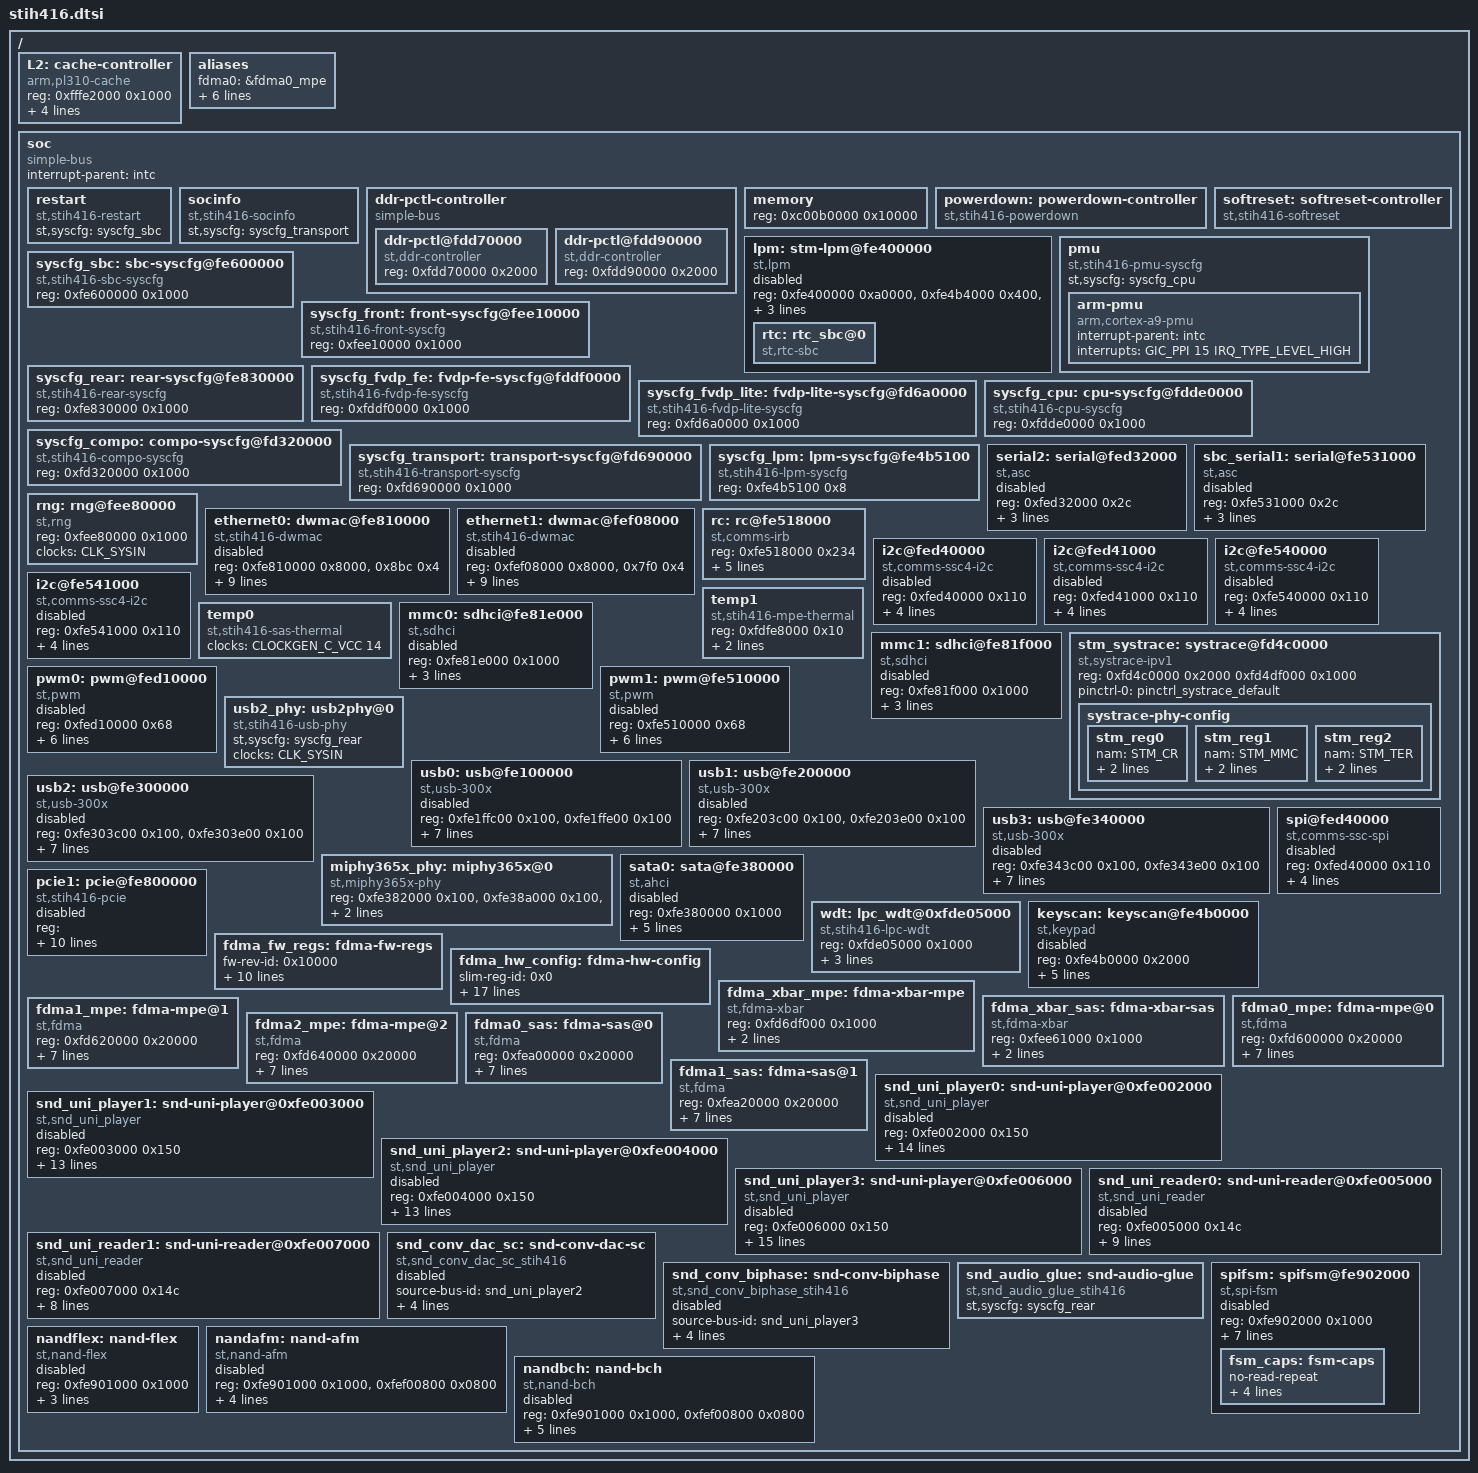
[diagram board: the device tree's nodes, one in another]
/*
 * Copyright (C) 2012 STMicroelectronics Limited.
 * Author: Srinivas Kandagatla <srinivas.kandagatla@st.com>
 *
 * This program is free software; you can redistribute it and/or modify
 * it under the terms of the GNU General Public License version 2 as
 * publishhed by the Free Software Foundation.
 */
#include <dt-bindings/interrupt-controller/arm-gic.h>
#include <dt-bindings/reset-controller/stih416-resets.h>
#include <dt-bindings/phy/phy-miphy365x.h>
#include "stih41x.dtsi"
#include "stih416-clock.dtsi"
#include "stih416-pinctrl.dtsi"
/ {
	L2: cache-controller {
		compatible = "arm,pl310-cache";
		reg = <0xfffe2000 0x1000>;
		arm,data-latency = <3 3 3>;
		arm,tag-latency = <2 2 2>;
		cache-unified;
		cache-level = <2>;
	};

	aliases {
		fdma0 = &fdma0_mpe;
		fdma1 = &fdma1_mpe;
		fdma2 = &fdma2_mpe;
		fdma3 = &fdma0_sas;
		fdma4 = &fdma1_sas;
		fdmaxbar0 = &fdma_xbar_mpe;
		fdmaxbar1 = &fdma_xbar_sas;
	};

	soc {
		#address-cells = <1>;
		#size-cells = <1>;
		interrupt-parent = <&intc>;
		ranges;
		compatible = "simple-bus";

		restart {
			compatible = "st,stih416-restart";
			st,syscfg = <&syscfg_sbc>;
		};

		socinfo {
			compatible = "st,stih416-socinfo";
			st,syscfg = <&syscfg_transport>;
		};

		ddr-pctl-controller {
			#address-cells = <1>;
			#size-cells = <1>;
			ranges;
			compatible = "simple-bus";
			ddr-pctl@fdd70000 {
				compatible = "st,ddr-controller";
				reg = <0xfdd70000 0x2000>;
			};
			ddr-pctl@fdd90000 {
				compatible = "st,ddr-controller";
				reg = <0xfdd90000 0x2000>;
			};
		};

		memory {
			device_type = "eram";
			reg = <0xc00b0000 0x10000>;
			reg-names = "eram_1";
		};

		powerdown: powerdown-controller {
			#reset-cells = <1>;
			compatible = "st,stih416-powerdown";
		};

		lpm:stm-lpm@fe400000 {
			compatible = "st,lpm";
			reg = <0xfe400000 0xa0000>,
			      <0xfe4b4000 0x400>,
			      <0xfe4b5100 0x100>,
			      <0x020000 0x0>;
			reg-names = "base", "mailbox", "confreg", "pmem";
			interrupts = <GIC_SPI 215 IRQ_TYPE_NONE>;
			st,fw_name = "lpm-fw-STiH416.elf";
			status = "disabled";

			rtc: rtc_sbc@0 {
				compatible = "st,rtc-sbc";
			};
		};

		softreset: softreset-controller {
			#reset-cells = <1>;
			compatible = "st,stih416-softreset";
		};

		pmu {
			compatible = "st,stih416-pmu-syscfg";
			st,syscfg = <&syscfg_cpu>;

			arm-pmu {
				interrupt-parent = <&intc>;
				compatible = "arm,cortex-a9-pmu";
				interrupts = <GIC_PPI 15 IRQ_TYPE_LEVEL_HIGH>;
			};
		};

		syscfg_sbc:sbc-syscfg@fe600000{
			compatible = "st,stih416-sbc-syscfg", "syscon";
			reg = <0xfe600000 0x1000>;
		};

		syscfg_front:front-syscfg@fee10000{
			compatible = "st,stih416-front-syscfg", "syscon";
			reg = <0xfee10000 0x1000>;
		};

		syscfg_rear:rear-syscfg@fe830000{
			compatible = "st,stih416-rear-syscfg", "syscon";
			reg = <0xfe830000 0x1000>;
		};

		/* MPE */
		syscfg_fvdp_fe:fvdp-fe-syscfg@fddf0000{
			compatible = "st,stih416-fvdp-fe-syscfg", "syscon";
			reg = <0xfddf0000 0x1000>;
		};

		syscfg_fvdp_lite:fvdp-lite-syscfg@fd6a0000{
			compatible = "st,stih416-fvdp-lite-syscfg", "syscon";
			reg = <0xfd6a0000 0x1000>;
		};

		syscfg_cpu:cpu-syscfg@fdde0000{
			compatible = "st,stih416-cpu-syscfg", "syscon";
			reg = <0xfdde0000 0x1000>;
		};

		syscfg_compo:compo-syscfg@fd320000{
			compatible = "st,stih416-compo-syscfg", "syscon";
			reg = <0xfd320000 0x1000>;
		};

		syscfg_transport:transport-syscfg@fd690000{
			compatible = "st,stih416-transport-syscfg", "syscon";
			reg = <0xfd690000 0x1000>;
		};

		syscfg_lpm:lpm-syscfg@fe4b5100{
			compatible = "st,stih416-lpm-syscfg", "syscon";
			reg = <0xfe4b5100 0x8>;
		};

		serial2: serial@fed32000{
			compatible = "st,asc";
			status = "disabled";
			reg = <0xfed32000 0x2c>;
			interrupts = <GIC_SPI 197 IRQ_TYPE_NONE>;
			clocks = <&CLK_S_A0_LS 0>;
			pinctrl-names = "default";
			pinctrl-0 = <&pinctrl_serial2 &pinctrl_serial2_oe>;
		};

		/* SBC_UART1 */
		sbc_serial1: serial@fe531000 {
			compatible = "st,asc";
			status = "disabled";
			reg = <0xfe531000 0x2c>;
			interrupts = <GIC_SPI 210 IRQ_TYPE_NONE>;
			pinctrl-names = "default";
			pinctrl-0 = <&pinctrl_sbc_serial1>;
			clocks = <&CLK_SYSIN>;
		};

		/* RNG */
		rng: rng@fee80000 {
			compatible = "st,rng";
			reg = <0xfee80000 0x1000>;
			clocks = <&CLK_SYSIN>;
		};

		ethernet0: dwmac@fe810000 {
			device_type = "network";
			status = "disabled";
			compatible = "st,stih416-dwmac", "snps,dwmac", "snps,dwmac-3.710";
			reg = <0xfe810000 0x8000>, <0x8bc 0x4>;
			reg-names = "stmmaceth", "sti-ethconf";
			st,syscon = <&syscfg_rear>;
			resets = <&softreset STIH416_ETH0_SOFTRESET>;
			reset-names = "stmmaceth";
			interrupts = <GIC_SPI 133 IRQ_TYPE_NONE>,
				     <GIC_SPI 134 IRQ_TYPE_NONE>,
				     <GIC_SPI 135 IRQ_TYPE_NONE>;

			interrupt-names = "macirq", "eth_wake_irq", "eth_lpi";

			snps,pbl = <32>;
			snps,mixed-burst;

			pinctrl-names = "default";
			pinctrl-0 = <&pinctrl_mii0>;
			clock-names = "stmmaceth",
				      "sti-ethclk";
			clocks = <&CLK_S_A1_LS 0>,
				 <&CLK_S_A1_LS 3>;
		};

		ethernet1: dwmac@fef08000 {
			device_type = "network";
			status = "disabled";
			compatible = "st,stih416-dwmac", "snps,dwmac", "snps,dwmac-3.710";
			reg = <0xfef08000 0x8000>, <0x7f0 0x4>;
			reg-names = "stmmaceth", "sti-ethconf";
			st,syscon = <&syscfg_sbc>;
			resets = <&softreset STIH416_ETH1_SOFTRESET>;
			reset-names = "stmmaceth";

			interrupts = <GIC_SPI 136 IRQ_TYPE_NONE>,
				     <GIC_SPI 137 IRQ_TYPE_NONE>,
				     <GIC_SPI 138 IRQ_TYPE_NONE>;

			interrupt-names = "macirq",
					  "eth_wake_irq",
					  "eth_lpi";

			snps,pbl = <32>;
			snps,mixed-burst;

			pinctrl-names = "default";
			pinctrl-0 = <&pinctrl_mii1>;
			clock-names = "stmmaceth", "sti-ethclk";
			clocks = <&CLK_S_A0_LS 0>,
				 <&CLK_S_A0_LS 4>;
		};

		rc: rc@fe518000 {
			compatible = "st,comms-irb";
			reg = <0xfe518000 0x234>;
			interrupts = <GIC_SPI 203 IRQ_TYPE_NONE>;
			rx-mode = "infrared";
			clocks = <&CLK_SYSIN>;
			pinctrl-names = "default";
			pinctrl-0 = <&pinctrl_ir>;
			resets = <&softreset STIH416_IRB_SOFTRESET>;
		};

		i2c@fed40000 {
			compatible = "st,comms-ssc4-i2c";
			reg = <0xfed40000 0x110>;
			interrupts = <GIC_SPI 187 IRQ_TYPE_LEVEL_HIGH>;
			#address-cells = <1>;
			#size-cells = <0>;
			clocks = <&CLK_S_A0_LS 0>;
			clock-names = "ssc";
			clock-frequency = <400000>;
			pinctrl-names = "default";
			pinctrl-0 = <&pinctrl_i2c0_default>;

			status = "disabled";
		};

		i2c@fed41000 {
			compatible = "st,comms-ssc4-i2c";
			reg = <0xfed41000 0x110>;
			interrupts = <GIC_SPI 188 IRQ_TYPE_LEVEL_HIGH>;
			#address-cells = <1>;
			#size-cells = <0>;
			clocks = <&CLK_S_A0_LS 0>;
			clock-names = "ssc";
			clock-frequency = <400000>;
			pinctrl-names = "default";
			pinctrl-0 = <&pinctrl_i2c1_default>;

			status = "disabled";
		};

		i2c@fe540000 {
			compatible = "st,comms-ssc4-i2c";
			reg = <0xfe540000 0x110>;
			interrupts = <GIC_SPI 206 IRQ_TYPE_LEVEL_HIGH>;
			#address-cells = <1>;
			#size-cells = <0>;
			clocks = <&CLK_SYSIN>;
			clock-names = "ssc";
			clock-frequency = <400000>;
			pinctrl-names = "default";
			pinctrl-0 = <&pinctrl_sbc_i2c0_default>;

			status = "disabled";
		};

		i2c@fe541000 {
			compatible = "st,comms-ssc4-i2c";
			reg = <0xfe541000 0x110>;
			interrupts = <GIC_SPI 207 IRQ_TYPE_LEVEL_HIGH>;
			#address-cells = <1>;
			#size-cells = <0>;
			clocks = <&CLK_SYSIN>;
			clock-names = "ssc";
			clock-frequency = <400000>;
			pinctrl-names = "default";
			pinctrl-0 = <&pinctrl_sbc_i2c1_default>;

			status = "disabled";
		};

		temp0{
			compatible = "st,stih416-sas-thermal";
			clock-names = "thermal";
			clocks = <&CLOCKGEN_C_VCC 14>;
		};

		temp1{
			compatible = "st,stih416-mpe-thermal";
			reg = <0xfdfe8000 0x10>;
			clock-names = "thermal";
			clocks = <&CLOCKGEN_E 3>;
			interrupts = <GIC_SPI 23 IRQ_TYPE_EDGE_RISING>;
		};

		mmc0: sdhci@fe81e000 {
			compatible = "st,sdhci";
			status = "disabled";
			reg = <0xfe81e000 0x1000>;
			interrupts = <GIC_SPI 127 IRQ_TYPE_NONE>;
			interrupt-names = "mmcirq";
			pinctrl-names = "default";
			pinctrl-0 = <&pinctrl_mmc0>;
			clock-names = "mmc";
			clocks = <&CLK_S_A1_LS 1>;
		};

		mmc1: sdhci@fe81f000 {
			compatible = "st,sdhci";
			status = "disabled";
			reg = <0xfe81f000 0x1000>;
			interrupts = <GIC_SPI 128 IRQ_TYPE_NONE>;
			interrupt-names = "mmcirq";
			pinctrl-names = "default";
			pinctrl-0 = <&pinctrl_mmc1>;
			clock-names = "mmc";
			clocks = <&CLK_S_A1_LS 8>;
		};

		stm_systrace: systrace@fd4c0000 {
			compatible = "st,systrace-ipv1";
			reg = <0xfd4c0000 0x2000
			       0xfd4df000 0x1000>;
			pinctrl-names = "default";
			pinctrl-0 = <&pinctrl_systrace_default>;

			/* STM IP v1 configuration */
			systrace-phy-config {
			    stm_reg0 { /* fck = 12.5Mhz */
				nam = "STM_CR";  ofs = <0x0000>; val = <0x00C0>;
			    };
			    stm_reg1 {
				nam = "STM_MMC"; ofs = <0x0008>; val = <0x0000>;
			    };
			    stm_reg2 { /* Enable all initiators */
				nam = "STM_TER"; ofs = <0x0010>; val = <0x023d>;
			    };
			};
		};

		/* SAS PWM MODULE */
		pwm0: pwm@fed10000 {
			compatible = "st,pwm";
			status = "disabled";
			#pwm-cells = <2>;
			reg = <0xfed10000 0x68>;
			pinctrl-names = "default";
			pinctrl-0 = <&pinctrl_pwm0_chan0_default
				     &pinctrl_pwm0_chan1_default
				     &pinctrl_pwm0_chan2_default
				     &pinctrl_pwm0_chan3_default>;
			clock-names = "pwm";
			clocks = <&CLK_SYSIN>;
			st,pwm-num-chan = <4>;
		};

		/* SBC PWM MODULE */
		pwm1: pwm@fe510000 {
			compatible = "st,pwm";
			status = "disabled";
			#pwm-cells = <2>;
			reg = <0xfe510000 0x68>;
			pinctrl-names = "default";
			pinctrl-0 = <&pinctrl_pwm1_chan0_default
				     &pinctrl_pwm1_chan1_default
				     &pinctrl_pwm1_chan2_default
				     &pinctrl_pwm1_chan3_default>;
			clock-names = "pwm";
			clocks = <&CLK_SYSIN>;
			st,pwm-num-chan = <4>;
		};

		usb2_phy: usb2phy@0 {
			compatible = "st,stih416-usb-phy";
			#phy-cells = <0>;

			st,syscfg = <&syscfg_rear>;

			clocks = <&CLK_SYSIN>;
			clock-names = "osc_phy";
		};

		usb0: usb@fe100000 {
			compatible = "st,usb-300x";
			status = "disabled";
			reg = <0xfe1ffc00 0x100>,
				  <0xfe1ffe00 0x100>;
			reg-names = "ohci", "ehci";

			interrupts = <GIC_SPI 148 IRQ_TYPE_NONE>,
				     <GIC_SPI 149 IRQ_TYPE_NONE>;
			interrupt-names = "ehci","ohci";
			pinctrl-names = "default";
			pinctrl-0 = <&pinctrl_usb0>;
			clocks = <&CLK_S_A1_LS 0>,
				 <&CLOCKGEN_B0 0>;
			clock-names = "ic", "ohci";

			resets = <&powerdown STIH416_USB0_POWERDOWN>,
				 <&softreset STIH416_USB0_SOFTRESET>;
			reset-names = "power", "softreset";

			phys = <&usb2_phy>;
			phy-names = "usb2-phy";
		};

		usb1: usb@fe200000 {
			compatible = "st,usb-300x";
			status = "disabled";
			reg = <0xfe203c00 0x100>,
			      <0xfe203e00 0x100>;
			reg-names = "ohci", "ehci";

			interrupts = <GIC_SPI 150 IRQ_TYPE_NONE>,
				     <GIC_SPI 151 IRQ_TYPE_NONE>;
			interrupt-names = "ehci","ohci";
			pinctrl-names = "default";
			pinctrl-0 = <&pinctrl_usb1>;
			clocks = <&CLK_S_A1_LS 0>,
				 <&CLOCKGEN_B0 0>;
			clock-names = "ic", "ohci";

			resets = <&powerdown STIH416_USB1_POWERDOWN>,
				 <&softreset STIH416_USB1_SOFTRESET>;
			reset-names = "power", "softreset";

			phys = <&usb2_phy>;
			phy-names = "usb2-phy";
		};

		usb2: usb@fe300000 {
			compatible = "st,usb-300x";
			status = "disabled";
			reg = <0xfe303c00 0x100>,
			      <0xfe303e00 0x100>;
			reg-names = "ohci", "ehci";

			interrupts = <GIC_SPI 152 IRQ_TYPE_NONE>,
				     <GIC_SPI 153 IRQ_TYPE_NONE>;
			interrupt-names = "ehci","ohci";
			pinctrl-names = "default";
			pinctrl-0 = <&pinctrl_usb2>;
			clocks = <&CLK_S_A1_LS 0>,
				 <&CLOCKGEN_B0 0>;
			clock-names = "ic", "ohci";

			resets = <&powerdown STIH416_USB2_POWERDOWN>,
				 <&softreset STIH416_USB2_SOFTRESET>;
			reset-names = "power", "softreset";

			phys = <&usb2_phy>;
			phy-names = "usb2-phy";
		};

		usb3: usb@fe340000 {
			compatible = "st,usb-300x";
			status = "disabled";
			reg = <0xfe343c00 0x100>, <0xfe343e00 0x100>;
			reg-names = "ohci", "ehci";

			interrupts = <GIC_SPI 154 IRQ_TYPE_NONE>,
				     <GIC_SPI 155 IRQ_TYPE_NONE>;
			interrupt-names = "ehci","ohci";
			pinctrl-names = "default";
			pinctrl-0 = <&pinctrl_usb3>;
			clocks = <&CLK_S_A1_LS 0>,
				 <&CLOCKGEN_B0 0>;
			clock-names = "ic", "ohci";

			resets = <&powerdown STIH416_USB3_POWERDOWN>,
				 <&softreset STIH416_USB3_SOFTRESET>;
			reset-names = "power", "softreset";

			phys = <&usb2_phy>;
			phy-names = "usb2-phy";
		};

		/* SSC0 */
		spi@fed40000 {
			compatible = "st,comms-ssc-spi";
			reg = <0xfed40000 0x110>;
			interrupts = <GIC_SPI 187 IRQ_TYPE_LEVEL_HIGH>;
			clocks = <&CLK_S_A0_LS 0>;
			clock-names = "ssc";
			pinctrl-names = "default";
			pinctrl-0 = <&pinctrl_spi0_default>;
			cs-gpios = <&PIO31 7>;

			status = "disabled";
		};

		miphy365x_phy: miphy365x@0 {
			compatible = "st,miphy365x-phy";
			#phy-cells = <1>;
			reg = <0xfe382000 0x100>,
			      <0xfe38a000 0x100>,
			      <0xfe394000 0x100>,
			      <0xfe804000 0x100>;
			reg-names = "sata0", "sata1", "pcie0", "pcie1";
			st,syscfg= <&syscfg_rear>;
		};

		sata0: sata@fe380000 {
			compatible = "st,ahci";
			reg = <0xfe380000 0x1000>;
			interrupts = <GIC_SPI 157 IRQ_TYPE_NONE>;
			interrupt-names = "hostc";
			status = "disabled";
			phys = <&miphy365x_phy MIPHY365X_SATA0_PORT0>;
			phy-names = "ahci_phy";
			resets = <&powerdown STIH416_SATA0_POWERDOWN>,
				 <&softreset STIH416_SATA0_SOFTRESET>;
			reset-names = "pwr-dwn", "sw-rst";
			clock-names = "ahci_clk";
			clocks = <&CLK_S_A0_LS 0>;
		};

		pcie1: pcie@fe800000 {
			compatible = "st,stih416-pcie";
			device_type = "pci";
			reg = <0xfe800000 0x00001000   /* cntrl registers */
			       0xfe808000 0x00000008   /* ahb registers */
			       0x2fff0000 0x00010000   /* configuration space */
			       0x40000000 0x80000000   /* lmi mem window */
			      0x82C 0x04>;            /* syscfg 2523 */
			reg-names = "pcie cntrl", "pcie ahb", "pcie cs", "mem-window",
				    "syscfg0";

			interrupts = <GIC_SPI 166 IRQ_TYPE_LEVEL_HIGH>,
				     <GIC_SPI 169 IRQ_TYPE_LEVEL_HIGH>,
				     <GIC_SPI 167 IRQ_TYPE_LEVEL_HIGH>;
			interrupt-names = "pcie inta", "pcie syserr", "msi";

			bus-range = <0x00 0xff>;
			#address-cells = <3>;
			#size-cells = <2>;
			ranges = <0x81000000 0 0x00008000 0x00008000 0 0x00008000   /* dummy I/O space */
				  0x82000000 0 0x20000000 0x20000000 0 0x05550000   /* non-prefetchable memory */
				  0xc2000000 0 0x25550000 0x25550000 0 0x0AAA0000>; /* prefetchable memory */
			st,syscfg = <&syscfg_rear>;
			st,ahb-fixup = <0x26C208>;

			resets = <&powerdown STIH416_PCIE1_POWERDOWN>,
				 <&softreset STIH416_PCIE1_SOFTRESET>;
			reset-names = "power", "softreset";

			phys = <&miphy365x_phy MIPHY365X_PCIE1_PORT1>;
			phy-names = "pcie_phy";

			status = "disabled";
		};

		wdt: lpc_wdt@0xfde05000 {
			compatible = "st,stih416-lpc-wdt";
			reg = <0xfde05000 0x1000>;
			clock-names = "lpc_wdt";
			clocks = <&CLOCKGEN_E 3>;
			timeout-sec = <600>;
			st,syscfg = <&syscfg_cpu>;
		};

		keyscan: keyscan@fe4b0000 {
			compatible = "st,keypad";
			status = "disabled";
			reg = <0xfe4b0000 0x2000>;
			interrupts = <GIC_SPI 212 IRQ_TYPE_NONE>;
			clocks = <&CLK_SYSIN>;
			pinctrl-names = "default";
			pinctrl-0 = <&pinctrl_keyscan>;
			resets = <&powerdown STIH416_KEYSCAN_POWERDOWN>,
				  <&softreset STIH416_KEYSCAN_SOFTRESET>;
		};

		/* FDMA */
		fdma_fw_regs: fdma-fw-regs {
			fw-rev-id = <0x10000>;
			fw-mchi-rx-nb-cur = <0x100c4>;
			fw-mchi-rx-nb-all = <0x100c8>;
			fw-cmd-statn = <0x10200>;
			fw-req-ctln = <0x10240>;
			fw-ptrn = <0x10800>;
			fw-ctrln = <0x10804>;
			fw-cntn = <0x10808>;
			fw-saddrn = <0x1080c>;
			fw-daddrn = <0x10810>;
			fw-node-size = <128>;
		};

		fdma_hw_config: fdma-hw-config {
			slim-reg-id = <0x0>;
			slim-reg-ver = <0x4>;
			slim-reg-en = <0x8>;
			slim-reg-clk-gate = <0xc>;
			slim-reg-slim-pc = <0x20>;

			dmem-offset = <0x10000>;
			dmem-size = <0x3000>;

			periph-reg-sync-reg = <0x17f88>;
			periph-reg-cmd-sta = <0x17fc0>;
			periph-reg-cmd-set = <0x17fc4>;
			periph-reg-cmd-clr = <0x17fc8>;
			periph-reg-cmd-mask = <0x17fcc>;
			periph-reg-int-sta = <0x17fd0>;
			periph-reg-int-set = <0x17fd4>;
			periph-reg-int-clr = <0x17fd8>;
			periph-reg-int-mask = <0x17fdc>;

			imem-offset = <0x18000>;
			imem-size = <0x8000>;
		};

		fdma_xbar_mpe: fdma-xbar-mpe {
			compatible = "st,fdma-xbar";
			reg = <0xfd6df000 0x1000>;
			first-fdma = <0>;
			last-fdma = <2>;
		};

		fdma_xbar_sas: fdma-xbar-sas {
			compatible = "st,fdma-xbar";
			reg = <0xfee61000 0x1000>;
			first-fdma = <3>;
			last-fdma = <4>;
		};

		fdma0_mpe: fdma-mpe@0 {
			compatible = "st,fdma";
			reg = <0xfd600000 0x20000>;
			interrupts = <GIC_SPI 10 IRQ_TYPE_NONE>;
			hw-conf = <&fdma_hw_config>;
			fw-regs = <&fdma_fw_regs>;
			xbar = <0>;
			fw-name = "fdma_STiH416_0.elf";
			clocks = <&CLK_M_A1_DIV0 1>,
				 <&CLK_M_A1_DIV1 5>,
				 <&CLK_M_A1_DIV1 5>,
				 <&CLK_M_A1_DIV1 5>;
			clock-names = "fdma_slim",
				      "fdma_hi",
				      "fdma_low",
				      "fdma_ic";
		};

		fdma1_mpe: fdma-mpe@1 {
			compatible = "st,fdma";
			reg = <0xfd620000 0x20000>;
			interrupts = <GIC_SPI 12 IRQ_TYPE_NONE>;
			hw-conf = <&fdma_hw_config>;
			fw-regs = <&fdma_fw_regs>;
			xbar = <0>;
			fw-name = "fdma_STiH416_1.elf";
			clocks = <&CLK_M_A1_DIV0 2>,
				 <&CLK_M_A1_DIV1 5>,
				 <&CLK_M_A1_DIV1 5>,
				 <&CLK_M_A1_DIV1 5>;
			clock-names = "fdma_slim",
				      "fdma_hi",
				      "fdma_low",
				      "fdma_ic";
		};

		fdma2_mpe: fdma-mpe@2 {
			compatible = "st,fdma";
			reg = <0xfd640000 0x20000>;
			interrupts = <GIC_SPI 14 IRQ_TYPE_NONE>;
			hw-conf = <&fdma_hw_config>;
			fw-regs = <&fdma_fw_regs>;
			xbar = <0>;
			fw-name = "fdma_STiH416_2.elf";
			clocks = <&CLK_M_A0_DIV0 2>,
				 <&CLK_M_A1_DIV1 5>,
				 <&CLK_M_A1_DIV1 5>,
				 <&CLK_M_A1_DIV1 5>;
			clock-names = "fdma_slim",
				      "fdma_hi",
				      "fdma_low",
				      "fdma_ic";
		};

		fdma0_sas: fdma-sas@0 {
			compatible = "st,fdma";
			reg = <0xfea00000 0x20000>;
			interrupts = <GIC_SPI 121 IRQ_TYPE_NONE>;
			hw-conf = <&fdma_hw_config>;
			fw-regs = <&fdma_fw_regs>;
			xbar = <1>;
			fw-name = "fdma_STiH416_3.elf";
			clocks = <&CLK_S_A0_HS 0>,
				 <&CLK_S_A0_LS 0>,
				 <&CLK_S_A0_LS 2>,
				 <&CLK_S_A0_LS 0>;
			clock-names = "fdma_slim",
				      "fdma_hi",
				      "fdma_low",
				      "fdma_ic";
		};

		fdma1_sas: fdma-sas@1 {
			compatible = "st,fdma";
			reg = <0xfea20000 0x20000>;
			interrupts = <GIC_SPI 124 IRQ_TYPE_NONE>;
			hw-conf = <&fdma_hw_config>;
			fw-regs = <&fdma_fw_regs>;
			xbar = <1>;
			fw-name = "fdma_STiH416_4.elf";
			clocks = <&CLK_S_A0_HS 1>,
				 <&CLK_S_A0_LS 0>,
				 <&CLK_S_A0_LS 2>,
				 <&CLK_S_A0_LS 0>;
			clock-names = "fdma_slim",
				      "fdma_hi",
				      "fdma_low",
				      "fdma_ic";
		};

		/* Uniperipheral */
		snd_uni_player0: snd-uni-player@0xfe002000 {
			compatible = "st,snd_uni_player";
			status = "disabled";
			reg = <0xfe002000 0x150>;
			interrupts = <GIC_SPI 140 IRQ_TYPE_NONE>;
			version = <2>;
			dmas = <&fdma0_sas>;
			dma-names = "stm-fdma.3";
			fdma-initiator = <0>;
			fdma-request-line = <23>;
			description = "Uni Player #0 (HDMI)";
			card-device = <0>;
			mode = "HDMI";
			iec958-lr-pol = <1>;
			iec958-i2s-mode = <1>;
			channels = <8>;
			parking = <0>;
			clocks = <&CLOCKGEN_B1 0>;
			clock-names = "uni_player_clk";
			auto-suspend-delay = <5000>;
		};

		snd_uni_player1: snd-uni-player@0xfe003000 {
			compatible = "st,snd_uni_player";
			status = "disabled";
			reg = <0xfe003000 0x150>;
			interrupts = <GIC_SPI 141 IRQ_TYPE_NONE>;
			version = <2>;
			dmas = <&fdma0_sas>;
			dma-names = "stm-fdma.3";
			fdma-initiator = <0>;
			fdma-request-line = <24>;
			description = "Uni Player #1 (PIO)";
			card-device = <1>;
			mode = "PCM";
			channels = <8>;
			parking = <0>;
			pinctrl-names = "default";
			pinctrl-0 = <>;
			clocks = <&CLOCKGEN_B1 1>;
			clock-names = "uni_player_clk";
			auto-suspend-delay = <5000>;
		};

		snd_uni_player2: snd-uni-player@0xfe004000 {
			compatible = "st,snd_uni_player";
			status = "disabled";
			reg = <0xfe004000 0x150>;
			interrupts = <GIC_SPI 142 IRQ_TYPE_NONE>;
			version = <2>;
			dmas = <&fdma0_sas>;
			dma-names = "stm-fdma.3";
			fdma-initiator = <0>;
			fdma-request-line = <25>;
			description = "Uni Player #2 (DAC)";
			card-device = <2>;
			mode = "PCM";
			channels = <2>;
			parking = <0>;
			s16-swap-lr = <1>;
			clocks = <&CLOCKGEN_B1 2>;
			clock-names = "uni_player_clk";
			auto-suspend-delay = <5000>;
		};

		snd_uni_player3: snd-uni-player@0xfe006000 {
			compatible = "st,snd_uni_player";
			status = "disabled";
			reg = <0xfe006000 0x150>;
			interrupts = <GIC_SPI 144 IRQ_TYPE_NONE>;
			version = <2>;
			dmas = <&fdma0_sas>;
			dma-names = "stm-fdma.3";
			fdma-initiator = <0>;
			fdma-request-line = <27>;
			description = "Uni Player #3 (SPDIF)";
			iec958-lr-pol = <0>;
			iec958-i2s-mode = <1>;
			card-device = <3>;
			mode = "SPDIF";
			channels = <2>;
			parking = <0>;
			pinctrl-names = "default";
			pinctrl-0 = <&pinctrl_spdif_out>;
			clocks = <&CLOCKGEN_B1 3>;
			clock-names = "uni_player_clk";
			auto-suspend-delay = <5000>;
		};

		snd_uni_reader0: snd-uni-reader@0xfe005000 {
			compatible = "st,snd_uni_reader";
			status = "disabled";
			reg = <0xfe005000 0x14c>;
			interrupts = <GIC_SPI 143 IRQ_TYPE_NONE>;
			version = <3>;
			dmas = <&fdma0_sas>;
			dma-names = "stm-fdma.3";
			fdma-initiator = <0>;
			fdma-request-line = <26>;
			description = "Uni Reader #0 (SPDIF)";
			card-device = <4>;
			channels = <2>;
			pinctrl-names = "default";
			pinctrl-0 = <&pinctrl_i2s_in>;
		};

		snd_uni_reader1: snd-uni-reader@0xfe007000 {
			compatible = "st,snd_uni_reader";
			status = "disabled";
			reg = <0xfe007000 0x14c>;
			interrupts = <GIC_SPI 145 IRQ_TYPE_NONE>;
			version = <3>;
			dmas = <&fdma0_sas>;
			dma-names = "stm-fdma.3";
			fdma-initiator = <0>;
			fdma-request-line = <22>;
			description = "Uni Reader #1 (HDMI)";
			card-device = <5>;
			channels = <2>;
		};

		snd_conv_dac_sc: snd-conv-dac-sc {
			compatible = "st,snd_conv_dac_sc_stih416";
			status = "disabled";
			source-bus-id = <&snd_uni_player2>;
			channel-to = <1>;
			channel-from = <0>;
			st,syscfg = <&syscfg_rear>;
			resets = <&softreset STIH416_AUD_DAC_SOFTRESET>;
			reset-names = "dac_nrst";
		};

		snd_conv_biphase: snd-conv-biphase {
			compatible = "st,snd_conv_biphase_stih416";
			status = "disabled";
			source-bus-id = <&snd_uni_player3>;
			channel-to = <1>;
			channel-from = <0>;
			idle-value = <0>;
			st,syscfg = <&syscfg_rear>;
		};

		snd_audio_glue: snd-audio-glue {
			compatible = "st,snd_audio_glue_stih416";
			status = "okay";
			st,syscfg = <&syscfg_rear>;
		};

		/* FSM */
		spifsm:	spifsm@fe902000{
			compatible = "st,spi-fsm";
			status = "disabled";
			reg = <0xfe902000 0x1000>;
			reg-names = "spi-fsm";
			clocks = <&CLK_S_A0_LS 3>;
			clock-names = "emi_clk";
			pinctrl-0 = <&pinctrl_fsm>;
			st,syscfg = <&syscfg_rear>;
			st,boot-device-reg = <0x958>;
			st,boot-device-spi = <0x1a>;
			st,boot-device-msk = <0x1f>;
			caps-handle = <&fsm_caps>;

			fsm_caps: fsm-caps {
				no-read-repeat;
				no-write-repeat;
				read-status-clkdiv4;
				dual-mode;		/* DUAL mode */
				quad-mode;		/* QUAD mode */
			};
		};

		nandflex: nand-flex {
			compatible = "st,nand-flex";
			reg = <0xfe901000 0x1000>;
			reg-names = "nand_mem";
			clocks = <&CLK_S_A0_LS 3>;
			clock-names = "emi_clk";
			st,flex-select-reg = <0xfef01000>;
			st,flex-select-msk = <0x40>;
			status = "disabled";
		};

		nandafm: nand-afm {
			compatible = "st,nand-afm";
			reg = <0xfe901000 0x1000>, <0xfef00800 0x0800>;
			reg-names = "nand_mem", "nand_dma";
			clocks = <&CLK_S_A0_LS 3>;
			clock-names = "emi_clk";
			interrupts = <GIC_SPI 139 IRQ_TYPE_NONE>;
			interrupt-names = "nand_irq";
			st,flex-select-reg = <0xfef01000>;
			st,flex-select-msk = <0x40>;
			status = "disabled";
		};

		nandbch: nand-bch {
			compatible = "st,nand-bch";
			reg = <0xfe901000 0x1000>, <0xfef00800 0x0800>;
			reg-names = "nand_mem", "nand_dma";
			clocks = <&CLK_S_A0_LS 3>, <&CLK_S_A1_LS 4>;
			clock-names = "emi_clk", "bch_clk";
			interrupts = <GIC_SPI 139 IRQ_TYPE_NONE>;
			interrupt-names = "nand_irq";
			st,bch-ecc-mode = "auto";
			st,bch-select-reg = <0xfef01000>;
			st,bch-select-msk = <0x40>;
			status = "disabled";
		};
	};
};
